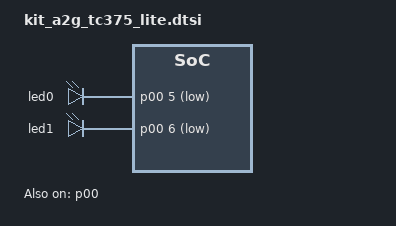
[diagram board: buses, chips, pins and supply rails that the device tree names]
/* Copyright (c) 2024 Infineon Technologies AG
 *
 * SPDX-License-Identifier: Apache-2.0
 */
#include "kit_a2g_tc375_lite-pinctrl.dtsi"

/ {
	leds {
		compatible = "gpio-leds";

		led0: led_0 {
			gpios = <&p00 5 GPIO_ACTIVE_LOW>;
		};

		led1: led_1 {
			gpios = <&p00 6 GPIO_ACTIVE_LOW>;
		};
	};

	aliases {
		led0 = &led0;
	};
};

arduino_serial: &asclin0 {
	compatible = "infineon,asclin-uart";
	pinctrl-0 = <&uart0_default>;
	pinctrl-names = "default";
};

&fosc {
	clock-frequency = <DT_FREQ_M(20)>;
	status = "okay";
};

&p00 {
	status = "okay";
	/* LED0 = P00.5 routed to GTM TIM3 channel 4 (mux input 1).
	 * Encoding matches gpio_tc3x_irq_source: pin=5, type=1 (GTM),
	 * cls=3 (TIM unit), ch=4, mux=1.
	 */
	irq-sources = <0x50001341>;
	interrupts = <IRQ_GTM_TIM3_4 2>;
};
